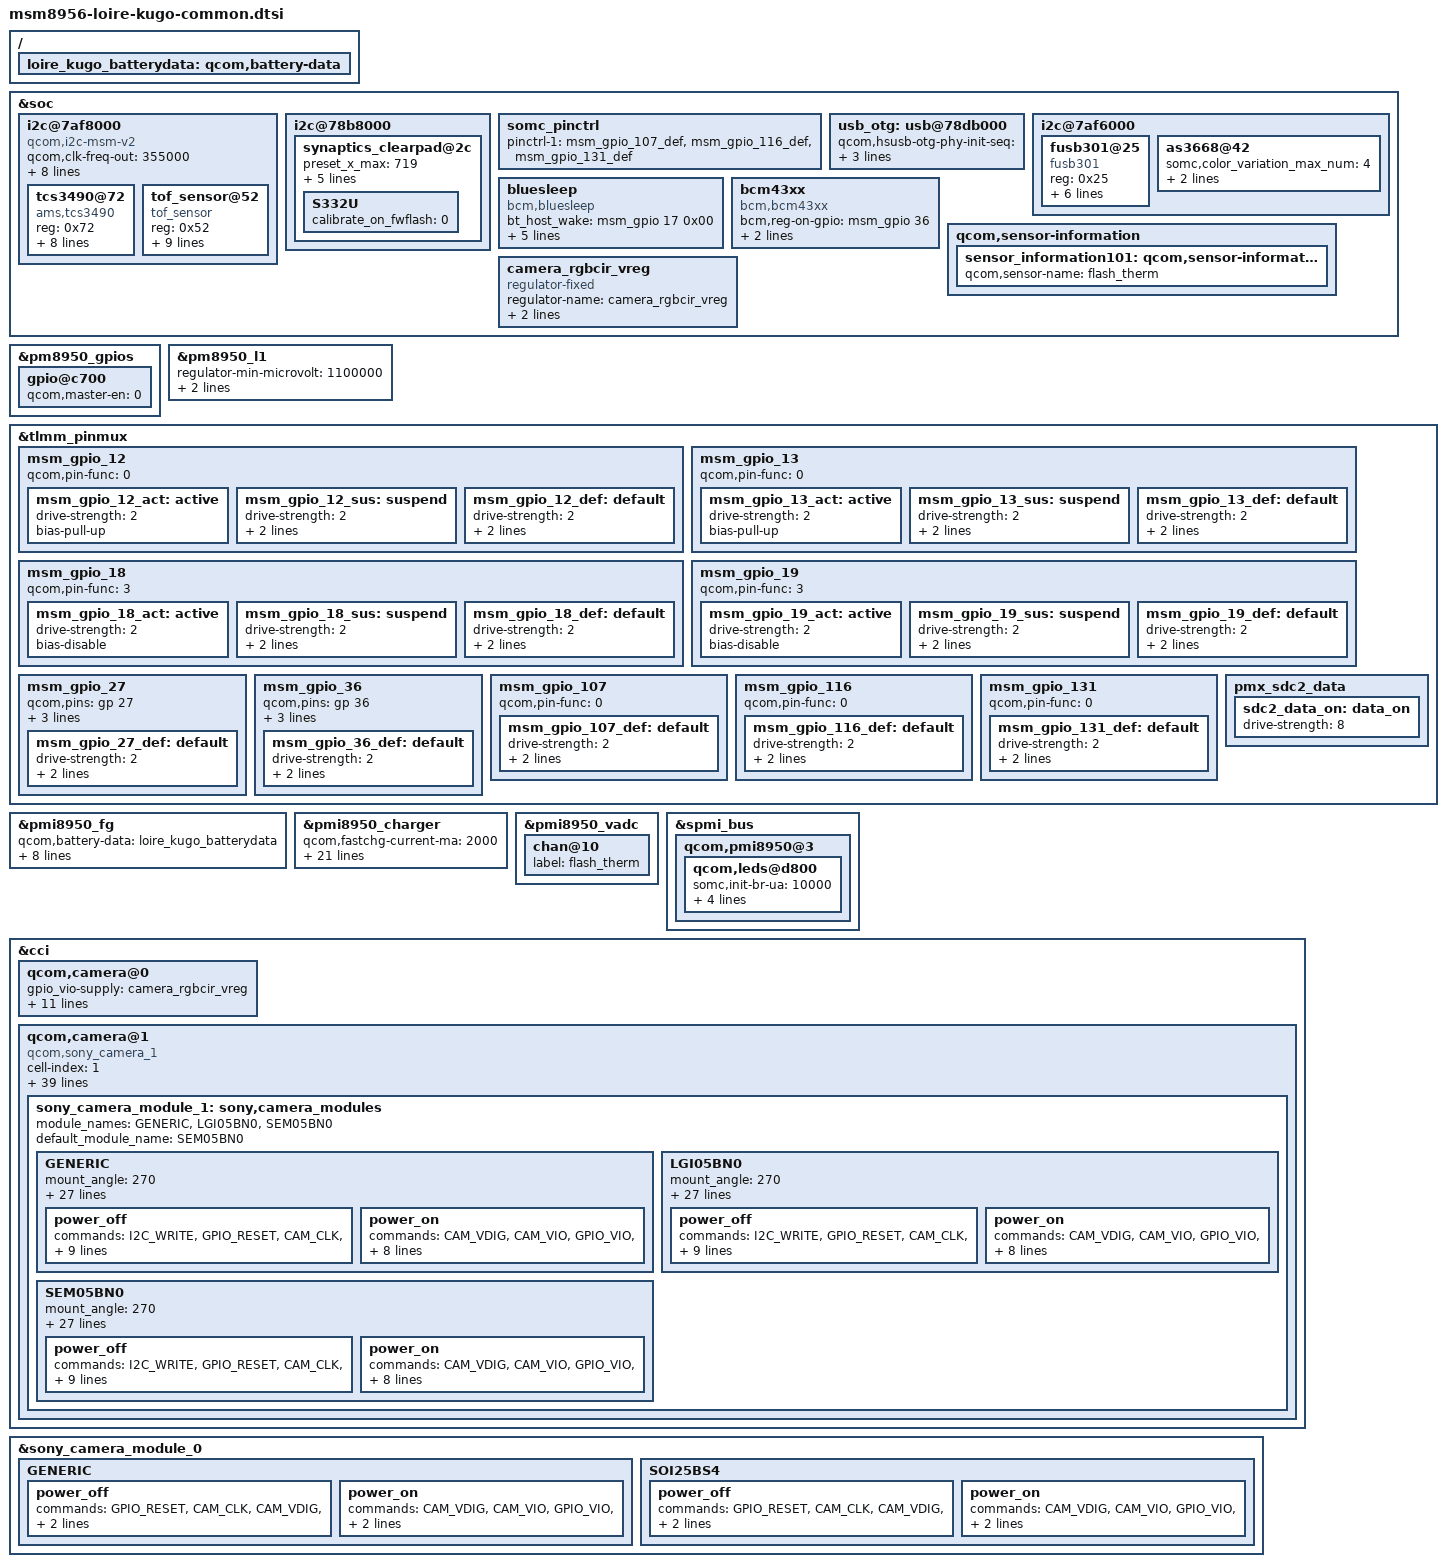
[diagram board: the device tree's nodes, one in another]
/* arch/arm/boot/dts/qcom/msm8956-loire-kugo-common.dtsi
 *
 * This program is free software; you can redistribute it and/or modify
 * it under the terms of the GNU General Public License version 2 and
 * only version 2 as published by the Free Software Foundation.
 *
 * This program is distributed in the hope that it will be useful,
 * but WITHOUT ANY WARRANTY; without even the implied warranty of
 * MERCHANTABILITY or FITNESS FOR A PARTICULAR PURPOSE.  See the
 * GNU General Public License for more details.
 */
/*
 * Copyright (C) 2016 Sony Mobile Communications Inc.
 *
 * This program is free software; you can redistribute it and/or modify
 * it under the terms of the GNU General Public License version 2, as
 * published by the Free Software Foundation.
 */

&soc {
	/* I2C : BLSP8 */
	i2c@7af8000 { /* BLSP2 QUP4 */
		compatible = "qcom,i2c-msm-v2";
		#address-cells = <1>;
		#size-cells = <0>;
		qcom,clk-freq-out = <355000>;
		qcom,clk-freq-in = <19200000>;

		qcom,master-id = <84>;
		reg-names = "qup_phys_addr";
		reg = <0x7AF8000 0x600>;
		interrupt-names = "qup_irq";
		interrupts = <0 302 0>;
		clock-names = "iface_clk", "core_clk";
		clocks = <&clock_gcc clk_gcc_blsp2_ahb_clk>,
			 <&clock_gcc clk_gcc_blsp2_qup4_i2c_apps_clk>;
		pinctrl-names = "i2c_active", "i2c_sleep";
		pinctrl-0 = <&msm_gpio_18_act &msm_gpio_19_act>;
		pinctrl-1 = <&msm_gpio_18_sus &msm_gpio_19_sus>;
		status = "okay";
		tcs3490@72 {
			compatible = "ams,tcs3490";
			reg = <0x72>;
			interrupt-parent = <&msm_gpio>;
			interrupts = <13 0x0>;
			rgbcir_vdd-supply = <&pm8950_l5>;
			ams,rgbcir-supply_name = "rgbcir_vdd";
			rgbcir_gpio_vdd-supply = <&camera_rgbcir_vreg>;
			ams,rgbcir-gpio-vreg-name = "rgbcir_gpio_vdd";
			pinctrl-names = "rgbcir_irq_active", "rgbcir_irq_suspend";
			pinctrl-0 = <&msm_gpio_13_act>;
			pinctrl-1 = <&msm_gpio_13_sus>;
		};
		tof_sensor@52 {
			compatible = "tof_sensor";
			reg = <0x52>;
			interrupt-parent = <&msm_gpio>;
			interrupts = <12 0x0>;
			tof_avdd-supply = <&pm8950_l5>;
			tof-supply_name = "tof_avdd";
			pinctrl-names = "tof_irq_active", "tof_irq_suspend";
			pinctrl-0 = <&msm_gpio_12_act>;
			pinctrl-1 = <&msm_gpio_12_sus>;
			sony,tof-sensor-name = "VL53L0";
			sony,tof-need-cam-on = <1>;
			sony,tof-sensor-facing = <0>;
		};
	};

	/* I2C : BLSP4 */
	i2c@78b8000 { /* BLSP1 QUP3 */
		synaptics_clearpad@2c {
			preset_x_max = <719>;
			preset_y_max = <1279>;

			/* Stamina Mode */
			stamina_mode_supported = <0x80000003>;

			/* F01_RMI_CTRL05: Doze Holdoff */
			doze_default_time = <50>;
			doze_glove_mode_time = <50>;
			doze_cover_mode_time = <50>;

			/* chip settings */
			S332U {
				calibrate_on_fwflash = <0>;
			};
		};
	};

	somc_pinctrl: somc_pinctrl {
		/* If variant specific default setting is needed,
		   fill pinctrl-1 value in <variant>.dtsi */
		pinctrl-1 = <&msm_gpio_107_def &msm_gpio_116_def
			&msm_gpio_131_def>;
	};

	usb_otg: usb@78db000 {
		qcom,hsusb-otg-phy-init-seq =
			<0x74 0x80 0x68 0x81 0x3f 0x82 0x33 0x83 0xffffffff>;
		qcom,hsusb-otg-phy-init-seq-host =
			<0x74 0x80 0x64 0x81 0x3f 0x82 0x33 0x83 0xffffffff>;
	};

	i2c@7af6000 { /* BLSP2 QUP2 */
		fusb301@25 {
			status = "okay";
			compatible = "fusb301";
			reg = <0x25>;
			interrupt-parent = <&msm_gpio>;
			interrupts = <107 0x3>, <131 0x2>;
			fusb301,cbl_sns-gpio = <&msm_gpio 116 0x00>;
			fusb301,int-gpio = <&msm_gpio 131 0x00>;
			fusb301,cbl_det-gpio = <&msm_gpio 107 0x00>;
			fusb301,use-try-snk-emulation;
		};
		as3668@42 {
			somc,color_variation_max_num = <4>;
			somc,max_current_uA = <14 9800 900 2800 1100 1200 1000
						15 7000 800 2000 800 1000 800
						16 11000 1100 2800 1100 1000 900
						17 12000 4500 2700 900 2000 2200>;
		};
	};

	bluesleep {
		compatible = "bcm,bluesleep";
		bt_host_wake = <&msm_gpio 17 0x00>; /* BT_HOST_WAKE */
		bt_ext_wake = <&msm_gpio 27 0x00>; /* BT_DEV_WAKE */
		interrupt-parent = <&msm_gpio>;
		interrupts = <17 0>;
		interrupt-names = "host_wake";
		pinctrl-names = "wake_irq_active", "wake_irq_suspend";
		pinctrl-0 = <&msm_gpio_17_act &msm_gpio_27_def>;
		pinctrl-1 = <&msm_gpio_17_sus &msm_gpio_27_def>;
	};

	bcm43xx {
		compatible = "bcm,bcm43xx";
		bcm,reg-on-gpio = <&msm_gpio 36 0x00>; /* BT_REG_ON */
		pinctrl-names = "default", "sleep";
		pinctrl-0 = <&msm_gpio_36_def>;
		pinctrl-1 = <&msm_gpio_36_def>;
	};

	qcom,sensor-information {
		sensor_information101: qcom,sensor-information@101 {
			qcom,sensor-name = "flash_therm";
		};
	};

	camera_rgbcir_vreg: camera_rgbcir_vreg {
		compatible = "regulator-fixed";
		regulator-name = "camera_rgbcir_vreg";
		startup-delay-us = <0>;
		gpio = <&msm_gpio 127 0>;
	};
};

/{
	loire_kugo_batterydata: qcom,battery-data {
		#include "batterydata-loire-kugo-send.dtsi"
	};
};

&pm8950_gpios {
	/* GPIO_8: NC (USB_ID_DET_N) */
	gpio@c700 {
		qcom,master-en = <0>;		/* Disable */
		status = "ok";
	};
};

/* Regulator config */
&pm8950_l1 {
	regulator-min-microvolt = <1100000>;
	regulator-max-microvolt = <1300000>;
	qcom,init-voltage = <1200000>;
	status = "okay";
};

&tlmm_pinmux {
	/* GPIO_12: TOF_INT */
	msm_gpio_12 {
		qcom,pin-func = <0>;
		msm_gpio_12_act: active {
			drive-strength = <2>;
			bias-pull-up;
		};
		msm_gpio_12_sus: suspend {
			drive-strength = <2>;
			bias-pull-down;
			input-enable;
		};
		msm_gpio_12_def: default {
			drive-strength = <2>;
			/delete-property/ bias-disable;
			/delete-property/ output-low;
			bias-pull-down;
			input-enable;
		};
	};

	/* GPIO_13: RGBC_IR_INT */
	msm_gpio_13 {
		qcom,pin-func = <0>;
		msm_gpio_13_act: active {
			drive-strength = <2>;
			bias-pull-up;
		};
		msm_gpio_13_sus: suspend {
			drive-strength = <2>;
			bias-pull-down;
			input-enable;
		};
		msm_gpio_13_def: default {
			drive-strength = <2>;
			/delete-property/ bias-disable;
			/delete-property/ output-low;
			bias-pull-down;
			input-enable;
		};
	};

	/* GPIO_18: RGBC-IR & ToF I2C SDA */
	msm_gpio_18 {
		qcom,pin-func = <3>;
		msm_gpio_18_act: active {
			drive-strength = <2>;
			bias-disable;
		};
		msm_gpio_18_sus: suspend {
			drive-strength = <2>;
			bias-pull-down;
			input-enable;
		};
		msm_gpio_18_def: default {
			drive-strength = <2>;
			/delete-property/ bias-disable;
			/delete-property/ output-low;
			bias-pull-down;
			input-enable;
		};
	};

	/* GPIO_19: RGBC-IR & ToF I2C SCL */
	msm_gpio_19 {
		qcom,pin-func = <3>;
		msm_gpio_19_act: active {
			drive-strength = <2>;
			bias-disable;
		};
		msm_gpio_19_sus: suspend {
			drive-strength = <2>;
			bias-pull-down;
			input-enable;
		};
		msm_gpio_19_def: default {
			drive-strength = <2>;
			/delete-property/ bias-disable;
			/delete-property/ output-low;
			bias-pull-down;
			input-enable;
		};
	};

	/* GPIO_27: BT_DEV_WAKE */
	msm_gpio_27 {
		qcom,pins = <&gp 27>;
		qcom,num-grp-pins = <1>;
		label = "msm_gpio_27";
		qcom,pin-func = <0>;
		msm_gpio_27_def: default {
			drive-strength = <2>;
			bias-disable;
			output-low;
		};
	};

	/* GPIO_36: BT_REG_ON */
	msm_gpio_36 {
		qcom,pins = <&gp 36>;
		qcom,num-grp-pins = <1>;
		label = "msm_gpio_36";
		qcom,pin-func = <0>;
		msm_gpio_36_def: default {
			drive-strength = <2>;
			bias-disable;
			output-low;
		};
	};

	/* GPIO_107: USB_CABLE_DET_N */
	msm_gpio_107 {
		qcom,pin-func = <0>;
		msm_gpio_107_def: default {
			drive-strength = <2>;
			bias-pull-up;
			input-enable;
		};
	};

	/* GPIO_116: USB_CABLE_SENSE_EN */
	msm_gpio_116 {
		qcom,pin-func = <0>;
		msm_gpio_116_def: default {
			drive-strength = <2>;
			bias-disable;
			output-low;
		};
	};

	/* GPIO_131: USB_CC_INT */
	msm_gpio_131 {
		qcom,pin-func = <0>;
		msm_gpio_131_def: default {
			drive-strength = <2>;
			/delete-property/ bias-disable;
			/delete-property/ output-low;
			bias-pull-up;
			input-enable;
		};
	};

	pmx_sdc2_data {
		sdc2_data_on: data_on {
			drive-strength = <8>;
		};
	};
};

&pmi8950_fg {
	qcom,battery-data = <&loire_kugo_batterydata>;
	qcom,cold-hot-jeita-hysteresis = <20 20>;
	qcom,fg-cc-cv-threshold-mv = <4340>;
	somc,cool-warm-jeita-hysteresis = <20 20>;
	somc,vfloat-arrangement;
	somc,vfloat-arrangement-threshold = <90>;
	somc,soc-magnification = <106>;
	somc,rated-capacity-enable;
	somc,rated-capacity-uah = <2700000>;
};

&pmi8950_charger {
	qcom,fastchg-current-ma = <2000>;
	somc,usb-9v-current-max = <1500>;
	qcom,float-voltage-comp = <0x08>;
	qcom,float-voltage-mv = <4350>;
	somc,fastchg-warm-current-ma = <700>;
	somc,fastchg-cool-current-ma = <700>;
	somc,thermal-engine-fastchg-current = <2000 1880 1600 1200 1000 700 500 300 300 300 300 300 300 0 0>;
	somc,thermal-mitigation-usb-5v = <2000 2000 2000 1500 1500 1500 1500 1500 1200 900 700 500 300 0 0>;
	somc,thermal-mitigation-usb-6v = <2000 2000 2000 1500 1500 1500 1500 1500 1200 900 700 500 300 0 0>;
	somc,thermal-mitigation-usb-7v = <1800 1800 1800 1500 1200 1200 1200 1200 1200 900 700 500 300 0 0>;
	somc,thermal-mitigation-usb-8v = <1600 1600 1600 1500 1100 1100 1100 1100 1200 900 700 500 300 0 0>;
	somc,thermal-mitigation-usb-9v = <1500 1500 1500 1500 1000 1000 1000 1000 1200 900 700 500 300 0 0>;
	somc,limit-usb-5v-level = <8>;
	/delete-property/ id_poll_enable;
	/delete-property/ id_poll_up_interval;
	/delete-property/ id_poll_up_period;
	/delete-property/ id_poll_pd_gpio;
	/delete-property/ id_poll_pd_invert;
	qcom,external-typec;
	qcom,typec-psy-name = "typec";
	somc,typec-current-max = <2000>;
};

&pmi8950_vadc {
	chan@10 {
		label = "flash_therm";
	};
};

&spmi_bus {
	qcom,pmi8950@3 {
		qcom,leds@d800 {
			somc,init-br-ua = <10000>;
			somc-s1,br-power-save-ua = <800>;
			qcom,led-strings-list = [00 01];
			qcom,ilim-ma = <660>;
			somc,bl-scale-enabled;
		};
	};
};

&cci {
	qcom,camera@0 {
		gpio_vio-supply = <&camera_rgbcir_vreg>;
		qcom,cam-vreg-name = "cam_vdig", "cam_vana", "cam_vio", "gpio_vio";
		qcom,cam-vreg-type = <0 0 1 0>;
		qcom,cam-vreg-min-voltage = <1200000 2700000 0 0>;
		qcom,cam-vreg-max-voltage = <1200000 2700000 0 0>;
		qcom,cam-vreg-op-mode = <333000 46000 0 0>;
		gpios = <&msm_gpio 26 0>, <&msm_gpio 35 0>;
		/delete-property/ qcom,gpio-vio;
		qcom,gpio-req-tbl-num = <0 1>;
		qcom,gpio-req-tbl-flags = <1 0>;
		qcom,gpio-req-tbl-label = "CAMIF_MCLK0", "CAM_RESET0";
	};
	qcom,camera@1 {
		cell-index = <1>;
		compatible = "qcom,sony_camera_1";
		reg = <0x1>;
		status = "ok";
		qcom,slave-id = <0x6c 0x0000 0x0000>;
		qcom,csiphy-sd-index = <1>;
		qcom,csid-sd-index = <1>;
		qcom,mount-angle = <0>;
		qcom,sensor-name = "sony_camera_1";
		cam_vdig-supply = <&pm8950_l1>;
		cam_vana-supply = <&pm8950_l10>;
		cam_vio-supply = <&pm8950_l5>;
		gpio_vio-supply = <&camera_rgbcir_vreg>;
		qcom,cam-vreg-name = "cam_vdig", "cam_vana", "cam_vio", "gpio_vio";
		qcom,cam-vreg-type = <0 0 1 0>;
		qcom,cam-vreg-min-voltage = <1200000 2700000 0 0>;
		qcom,cam-vreg-max-voltage = <1200000 2700000 0 0>;
		qcom,cam-vreg-op-mode = <333000 46000 0 0>;
		qcom,gpio-no-mux = <0>;
		pinctrl-names = "cam_default", "cam_suspend";
		pinctrl-0 = <&cam_sensor_mclk2_default &cam_sensor_front_default>;
		pinctrl-1 = <&cam_sensor_mclk2_sleep &cam_sensor_front_sleep>;
		gpios = <&msm_gpio 28 0>, <&msm_gpio 38 0>;
		qcom,gpio-reset = <1>;
		/delete-property/ qcom,gpio-vio;
		qcom,gpio-req-tbl-num = <0 1>;
		qcom,gpio-req-tbl-flags = <1 0>;
		qcom,gpio-req-tbl-label = "CAMIF_MCLK2", "CAM_RESET2";
		qcom,csi-lane-assign = <0x4320>;
		qcom,csi-lane-mask = <0x7>;
		qcom,sensor-position = <1>;
		qcom,sensor-mode = <1>;
		qcom,cci-master = <1>;
		clocks = <&clock_gcc clk_mclk2_clk_src>, <&clock_gcc clk_gcc_camss_mclk2_clk>;
		clock-names = "cam_src_clk", "cam_clk";
		sony,i2c_addr = <0x6c>;
		sony,eeprom_addr = <0xA0>;
		sony,eeprom_type = <0>;
		sony,eeprom_max_len = <1024>;
		sony,subdev_code = <0x3007>;
		sony_camera_module_1: sony,camera_modules {
		    status = "disabled";
		};
	};
};

&sony_camera_module_0 {
	GENERIC {
		power_off {
			commands =
				"GPIO_RESET",
				"CAM_CLK",
				"CAM_VDIG",
				"GPIO_VIO",
				"CAM_VIO",
				"CAM_VANA",
				"CAM_VAF",
				"EXIT";
			GPIO_VIO = <5 0xFFFFFFFF 0 1>;
		};
		power_on {
			commands =
				"CAM_VDIG",
				"CAM_VIO",
				"GPIO_VIO",
				"CAM_VANA",
				"CAM_VAF",
				"CAM_CLK",
				"GPIO_RESET",
				"EXIT";
			GPIO_VIO = <5 0 0 1>;
		};
	};
	SOI25BS4 {
		power_off {
			commands =
				"GPIO_RESET",
				"CAM_CLK",
				"CAM_VDIG",
				"GPIO_VIO",
				"CAM_VIO",
				"CAM_VANA",
				"CAM_VAF",
				"EXIT";
			GPIO_VIO = <5 0xFFFFFFFF 0 1>;
		};
		power_on {
			commands =
				"CAM_VDIG",
				"CAM_VIO",
				"GPIO_VIO",
				"CAM_VANA",
				"CAM_VAF",
				"CAM_CLK",
				"GPIO_RESET",
				"EXIT";
			GPIO_VIO = <5 0 0 1>;
		};
	};
};

&sony_camera_module_1 {
	module_names = "GENERIC", "LGI05BN0", "SEM05BN0";
	default_module_name = "SEM05BN0";
	status = "ok";
	/delete-property/ SOI13BS0;
	/delete-property/ SEM13BS0;

	GENERIC {
		mount_angle = <270>;
		sensor_rotation = <180>;
		sensor_facing = <1>;
		total_pixel_number_w = <2608>;
		total_pixel_number_h = <2000>;
		active_pixel_number_x = <8>;
		active_pixel_number_y = <8>;
		active_pixel_number_w = <2592>;
		active_pixel_number_h = <1944>;
		min_focus_distance = <0>;
		hyper_focal_distance = <0>;
		diagonal_len = "3.63";
		unit_cell_size_w = "1.12";
		unit_cell_size_h = "1.12";
		min_f_number = "2.40";
		max_f_number = "2.40";
		has_3a = <0>;
		has_focus_actuator = <0>;
		need_standby_af = <0>;
		i2c_freq_mode = <0>;
		has_pdaf = <0>;
		has_rs = <1>;
		pdaf_free_area_num = <0>;
		pdaf_fixed_area_size_w = <0>;
		pdaf_fixed_area_size_h = <0>;
		pll_num = <26>;
		pll = <145 109 112 112 122 109 182 75 112 136 145 182 182 145 142 175 104 182 145 145 182 182 182 182 104 112>;
		power_off {
			commands =
				"I2C_WRITE",
				"GPIO_RESET",
				"CAM_CLK",
				"CAM_VANA",
				"GPIO_VIO",
				"CAM_VIO",
				"CAM_VDIG",
				"EXIT";
			CAM_VDIG = <0 0xFFFFFFFF 0 98>;
			CAM_VIO = <1 0xFFFFFFFF 0 1>;
			CAM_VANA = <2 0xFFFFFFFF 0 1>;
			GPIO_VIO = <5 0xFFFFFFFF 0 1>;
			GPIO_RESET = <8 0x0 0 1>;
			CAM_CLK = <9 0xFFFFFFFF 0 1>;
			I2C_WRITE = <10 0x0100 0 100>;
			EXIT = <11 0x0 0 0>;
		};
		power_on {
			commands =
				"CAM_VDIG",
				"CAM_VIO",
				"GPIO_VIO",
				"CAM_VANA",
				"GPIO_RESET",
				"CAM_CLK",
				"EXIT";
			CAM_VDIG = <0 1200 85000 1>;
			CAM_VIO = <1 0 0 1>;
			CAM_VANA = <2 2700 103000 1>;
			GPIO_VIO = <5 0 0 1>;
			GPIO_RESET = <8 1 0 1>;
			CAM_CLK = <9 0 0 1>;
			EXIT = <11 0x0 0 0>;
		};
	};
	LGI05BN0 {
		mount_angle = <270>;
		sensor_rotation = <180>;
		sensor_facing = <1>;
		total_pixel_number_w = <2608>;
		total_pixel_number_h = <2000>;
		active_pixel_number_x = <8>;
		active_pixel_number_y = <8>;
		active_pixel_number_w = <2592>;
		active_pixel_number_h = <1944>;
		min_focus_distance = <0>;
		hyper_focal_distance = <0>;
		diagonal_len = "3.63";
		unit_cell_size_w = "1.12";
		unit_cell_size_h = "1.12";
		min_f_number = "2.40";
		max_f_number = "2.40";
		has_3a = <0>;
		has_focus_actuator = <0>;
		need_standby_af = <0>;
		i2c_freq_mode = <0>;
		has_pdaf = <0>;
		has_rs = <1>;
		pdaf_free_area_num = <0>;
		pdaf_fixed_area_size_w = <0>;
		pdaf_fixed_area_size_h = <0>;
		pll_num = <26>;
		pll = <118 118 95 118 125 118 118 125 118 118 118 118 118 118 118 118 118 118 118 118 118 118 118 118 118 118>;
		power_off {
			commands =
				"I2C_WRITE",
				"GPIO_RESET",
				"CAM_CLK",
				"CAM_VANA",
				"GPIO_VIO",
				"CAM_VIO",
				"CAM_VDIG",
				"EXIT";
			CAM_VDIG = <0 0xFFFFFFFF 0 98>;
			CAM_VIO = <1 0xFFFFFFFF 0 1>;
			CAM_VANA = <2 0xFFFFFFFF 0 1>;
			GPIO_VIO = <5 0xFFFFFFFF 0 1>;
			GPIO_RESET = <8 0x0 0 1>;
			CAM_CLK = <9 0xFFFFFFFF 0 1>;
			I2C_WRITE = <10 0x0100 0 100>;
			EXIT = <11 0x0 0 0>;
		};
		power_on {
			commands =
				"CAM_VDIG",
				"CAM_VIO",
				"GPIO_VIO",
				"CAM_VANA",
				"GPIO_RESET",
				"CAM_CLK",
				"EXIT";
			CAM_VDIG = <0 1200 85000 1>;
			CAM_VIO = <1 0 0 1>;
			CAM_VANA = <2 2700 103000 1>;
			GPIO_VIO = <5 0 0 1>;
			GPIO_RESET = <8 1 0 1>;
			CAM_CLK = <9 0 0 1>;
			EXIT = <11 0x0 0 0>;
		};
	};
	SEM05BN0 {
		mount_angle = <270>;
		sensor_rotation = <180>;
		sensor_facing = <1>;
		total_pixel_number_w = <2608>;
		total_pixel_number_h = <2000>;
		active_pixel_number_x = <8>;
		active_pixel_number_y = <8>;
		active_pixel_number_w = <2592>;
		active_pixel_number_h = <1944>;
		min_focus_distance = <0>;
		hyper_focal_distance = <0>;
		diagonal_len = "3.63";
		unit_cell_size_w = "1.12";
		unit_cell_size_h = "1.12";
		min_f_number = "2.40";
		max_f_number = "2.40";
		has_3a = <0>;
		has_focus_actuator = <0>;
		need_standby_af = <0>;
		i2c_freq_mode = <0>;
		has_pdaf = <0>;
		has_rs = <1>;
		pdaf_free_area_num = <0>;
		pdaf_fixed_area_size_w = <0>;
		pdaf_fixed_area_size_h = <0>;
		pll_num = <26>;
		pll = <118 118 95 118 125 118 118 125 118 118 118 118 118 118 118 118 118 118 118 118 118 118 118 118 118 118>;
		power_off {
			commands =
				"I2C_WRITE",
				"GPIO_RESET",
				"CAM_CLK",
				"CAM_VANA",
				"GPIO_VIO",
				"CAM_VIO",
				"CAM_VDIG",
				"EXIT";
			CAM_VDIG = <0 0xFFFFFFFF 0 98>;
			CAM_VIO = <1 0xFFFFFFFF 0 1>;
			CAM_VANA = <2 0xFFFFFFFF 0 1>;
			GPIO_VIO = <5 0xFFFFFFFF 0 1>;
			GPIO_RESET = <8 0x0 0 1>;
			CAM_CLK = <9 0xFFFFFFFF 0 1>;
			I2C_WRITE = <10 0x0100 0 100>;
			EXIT = <11 0x0 0 0>;
		};
		power_on {
			commands =
				"CAM_VDIG",
				"CAM_VIO",
				"GPIO_VIO",
				"CAM_VANA",
				"GPIO_RESET",
				"CAM_CLK",
				"EXIT";
			CAM_VDIG = <0 1200 85000 1>;
			CAM_VIO = <1 0 0 1>;
			CAM_VANA = <2 2700 103000 1>;
			GPIO_VIO = <5 0 0 1>;
			GPIO_RESET = <8 1 0 1>;
			CAM_CLK = <9 0 0 1>;
			EXIT = <11 0x0 0 0>;
		};
	};
};
